# CortexM_SCB register map
File version: 1.0
Cortex-M System Control Block (test subset)
Registers are 32-bit, read-only, reset 0x0 unless marked. A register's access mark holds for its fields unless they carry their own. Offsets are from the block's base; lines under a group give offsets from that group; [hi:lo] are bit positions; {n}, {i} and the like mark numbered series; 'fields as' and 'values as' point back to an identical list; <NAME> marks a mode.

## Memory map
0xE000ED00 SCB size 0x40 — System Control Block

## SCB — System Control Block
Base 0xE000ED00
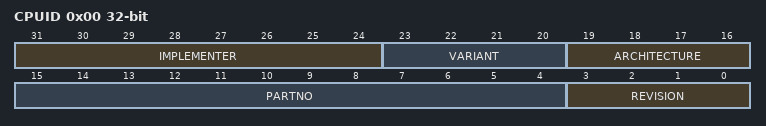
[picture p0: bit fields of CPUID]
0x00 CPUID — CPUID Base Register
  [31:24] IMPLEMENTER, [23:20] VARIANT, [19:16] ARCHITECTURE, [15:4] PARTNO, [3:0] REVISION
0x08 VTOR rw — Vector Table Offset Register
